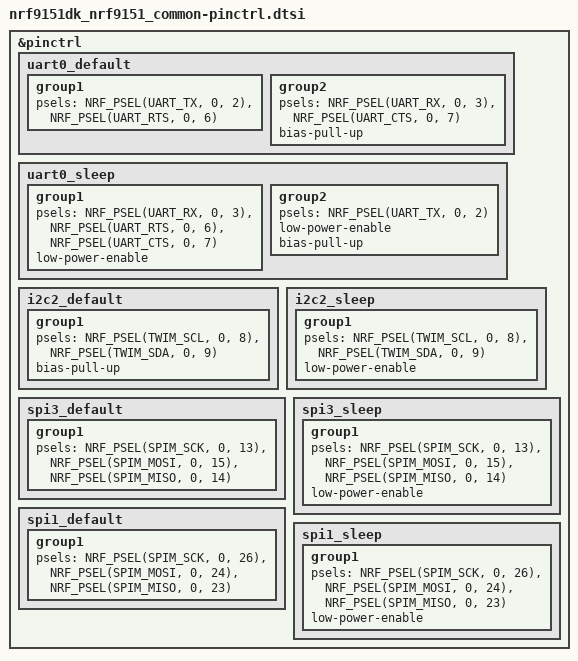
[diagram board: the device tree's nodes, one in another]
/*
 * Copyright (c) 2023 Nordic Semiconductor
 * SPDX-License-Identifier: Apache-2.0
 */

&pinctrl {
	uart0_default: uart0_default {
		group1 {
			psels = <NRF_PSEL(UART_TX, 0, 2)>,
				<NRF_PSEL(UART_RTS, 0, 6)>;
		};

		group2 {
			psels = <NRF_PSEL(UART_RX, 0, 3)>,
				<NRF_PSEL(UART_CTS, 0, 7)>;
			bias-pull-up;
		};
	};

	uart0_sleep: uart0_sleep {
		group1 {
			psels = <NRF_PSEL(UART_RX, 0, 3)>,
				<NRF_PSEL(UART_RTS, 0, 6)>,
				<NRF_PSEL(UART_CTS, 0, 7)>;
			low-power-enable;
		};

		group2 {
			psels = <NRF_PSEL(UART_TX, 0, 2)>;
			low-power-enable;
			bias-pull-up;
		};
	};

	i2c2_default: i2c2_default {
		group1 {
			psels = <NRF_PSEL(TWIM_SCL, 0, 8)>,
				<NRF_PSEL(TWIM_SDA, 0, 9)>;
			bias-pull-up;
		};
	};

	i2c2_sleep: i2c2_sleep {
		group1 {
			psels = <NRF_PSEL(TWIM_SCL, 0, 8)>,
				<NRF_PSEL(TWIM_SDA, 0, 9)>;
			low-power-enable;
		};
	};

	spi3_default: spi3_default {
		group1 {
			psels = <NRF_PSEL(SPIM_SCK,  0, 13)>,
				<NRF_PSEL(SPIM_MOSI, 0, 15)>,
				<NRF_PSEL(SPIM_MISO, 0, 14)>;
		};
	};

	spi3_sleep: spi3_sleep {
		group1 {
			psels = <NRF_PSEL(SPIM_SCK,  0, 13)>,
				<NRF_PSEL(SPIM_MOSI, 0, 15)>,
				<NRF_PSEL(SPIM_MISO, 0, 14)>;
			low-power-enable;
		};
	};

	/* SPI1 → nRF7000 Wi-Fi chip. Peripheral 1 chosen because peripherals
	 * 0 (uart0), 2 (i2c2), and 3 (spi3) are taken; only peripheral 1
	 * was free on the 9151's SERIAL constraint.
	 *   SCK  = P0.26
	 *   MOSI = P0.24
	 *   MISO = P0.23
	 *   CS   = P0.25 (managed via cs-gpios in &spi1, not pinctrl)
	 */
	spi1_default: spi1_default {
		group1 {
			psels = <NRF_PSEL(SPIM_SCK,  0, 26)>,
				<NRF_PSEL(SPIM_MOSI, 0, 24)>,
				<NRF_PSEL(SPIM_MISO, 0, 23)>;
		};
	};

	spi1_sleep: spi1_sleep {
		group1 {
			psels = <NRF_PSEL(SPIM_SCK,  0, 26)>,
				<NRF_PSEL(SPIM_MOSI, 0, 24)>,
				<NRF_PSEL(SPIM_MISO, 0, 23)>;
			low-power-enable;
		};
	};
};
